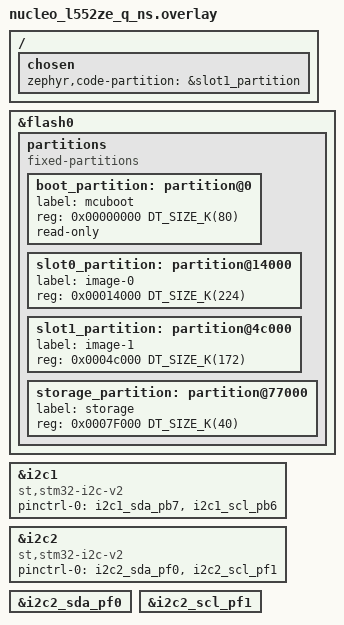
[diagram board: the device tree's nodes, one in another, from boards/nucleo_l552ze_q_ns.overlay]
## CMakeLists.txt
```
cmake_minimum_required(VERSION 3.20.0)

find_package(Zephyr REQUIRED HINTS $ENV{ZEPHYR_BASE})
project(i2c_sensor_trusted)

target_sources(app PRIVATE
  src/main.c
  src/trusted_peripheral_ns.c
)

# NOTE force test flash layout for more flash memory
set_property(TARGET zephyr_property_target
             APPEND PROPERTY TFM_CMAKE_OPTIONS
             -DTFM_S_REG_TEST=ON
)

get_target_property(TFM_BINARY_DIR tfm TFM_BINARY_DIR)
configure_file(
  ${CMAKE_CURRENT_LIST_DIR}/trusted_peripheral/tfm_manifest_list.yaml.in
  ${CMAKE_CURRENT_BINARY_DIR}/trusted_peripheral/tfm_manifest_list.yaml
)

set_property(TARGET zephyr_property_target
  APPEND PROPERTY TFM_CMAKE_OPTIONS
  -DTFM_EXTRA_MANIFEST_LIST_FILES=${CMAKE_CURRENT_BINARY_DIR}/trusted_peripheral/tfm_manifest_list.yaml
  -DTFM_EXTRA_PARTITION_PATHS=${CMAKE_CURRENT_LIST_DIR}/trusted_peripheral
)

# include folder that has tfm_api.h
target_include_directories(app PRIVATE
  $<TARGET_PROPERTY:tfm,TFM_BINARY_DIR>/install/interface/include
)

target_compile_definitions(app
    PRIVATE TFM_PARTITION_TRUSTED_PERIPHERAL
)
```

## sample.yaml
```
sample:
  name: Hello trusted I2C
```

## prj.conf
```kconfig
#
# SENSOR
#
CONFIG_GPIO=y
CONFIG_I2C=y
CONFIG_I2C_STM32=y

CONFIG_SPI=y
CONFIG_SPI_STM32=y

# NOTE a combination of these enables "%f" for printk
CONFIG_SHELL=y
CONFIG_I2C_SHELL=y
CONFIG_SENSOR_SHELL=y
CONFIG_SENSOR=y

#
# PARTITION
#
CONFIG_BUILD_WITH_TFM=y
CONFIG_TFM_PROFILE_TYPE_NOT_SET=y

# The TF-M build system produces an interface source file for accessing
# connection based services. Select this option when TF-M service models
# requires this source file. Note: This is an auto-generated configuration in
# the TF-M build system. When this option is not enabled in the TF-M build
# system this will result in compilation error.
CONFIG_TFM_CONNECTION_BASED_SERVICE_API=y
```

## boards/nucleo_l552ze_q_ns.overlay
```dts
/ {
	chosen {
		zephyr,code-partition = &slot1_partition;
	};
};

&flash0 {

	partitions {
		compatible = "fixed-partitions";
		#address-cells = <1>;
		#size-cells = <1>;

		boot_partition: partition@0 {
			label = "mcuboot";
			reg = <0x00000000 DT_SIZE_K(80)>;
			read-only;
		};
		/* Secure image primary slot */
		slot0_partition: partition@14000 {
			label = "image-0";
			reg = <0x00014000 DT_SIZE_K(224)>;
		};
		/* Non-secure image primary slot */
		slot1_partition: partition@4c000 {
			label = "image-1";
			reg = <0x0004c000 DT_SIZE_K(172)>;
		};
		/*
		 * The flash starting at 0x7F000 and ending at
		 * 0x80000 is reserved for the application.
		 */
		storage_partition: partition@77000 {
			label = "storage";
			reg = <0x0007F000 DT_SIZE_K(40)>;
		};
	};
};

&i2c1 {
			compatible = "st,stm32-i2c-v2";
            status = "okay";
            /* sda-pin = <26>; */
            /* scl-pin = <27>; */

            /* pinctrl-0 = <>; */
            pinctrl-0 = <&i2c1_sda_pb7 &i2c1_scl_pb6>;
            pinctrl-names = "default";
};

&i2c2 {
			compatible = "st,stm32-i2c-v2";
            status = "okay";
            /* sda-pin = <26>; */
            /* scl-pin = <27>; */

            pinctrl-0 = <&i2c2_sda_pf0 &i2c2_scl_pf1>;
            pinctrl-names = "default";
};

&i2c2_sda_pf0 {
            /* /delete-property/ bias-pull-up;     */
            /* /delete-property/ drive-open-drain; */
};

&i2c2_scl_pf1 {
            /* /delete-property/ bias-pull-up;     */
            /* /delete-property/ drive-open-drain; */
            /* bias-disable */
            /* bias-pull-up */
            /* bias-pull-down */
            /* drive-push-pull */
            /* drive-open-drain */
            /* output-low */
            /* output-high */
};
```

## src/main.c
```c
#include <zephyr/kernel.h>

/* partition includes */
#include <tfm_ns_interface.h>
#include "trusted_peripheral_ns.h"

/* sensor includes */
#include <zephyr/device.h>
#include <zephyr/drivers/gpio.h>
#include <zephyr/drivers/i2c.h>
#define I2C_SLAVE_ADDR 0x28


/* TODO duplicated on secure side */
#define MAC_HASH_SIZE 256
typedef struct {
    uint8_t buf[MAC_HASH_SIZE];  /* lets assume our data packet fits into this buffer */
} tp_mac_t;

int main(void)
{
    tp_mac_t mac = {0};

    /* sensor code */
    for (;;)
    {
        uint32_t tick_begin = HAL_GetTick(); /* TODO by default the tick increments for every ms.
                                              * is that accurate enough to measure performance ? */

        float sensor_temperature = 0.0f;
        float sensor_humidity    = 0.0f;

        /* i2c code in secure code */
        psa_status_t ret = tp_sensor_data_get(&sensor_temperature, &sensor_humidity, &mac, sizeof(tp_mac_t));
        if (ret != PSA_SUCCESS) {
            printk("Getting sensor data failed with status: %i\n", ret);
        }

        uint32_t tick_end = HAL_GetTick();
        printk("(%u ms) ", tick_end - tick_begin);

        printk("Temp: %f ", sensor_temperature);
        printk("Humidity: %f\n", sensor_humidity);

        /*
        printk("MAC: ");
        for (int i = 0; i < 32; i++)
        {
            printk("%02x", mac.buf[i]);
        }
        printk("\n");
        */
    }

    return 0;
}
```

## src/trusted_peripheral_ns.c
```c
#include <tfm_ns_interface.h>

#include "trusted_peripheral_ns.h"

#if defined(CONFIG_TFM_IPC)
#include "psa/client.h"
#include "psa_manifest/sid.h"
#endif

psa_status_t tp_sensor_data_get(float* temp, float* humidity, void* mac, size_t mac_size)
{
    psa_status_t status;
    psa_handle_t handle;

    psa_invec  in_vec[]  = { { .base = NULL, .len = 0 } }; // input parameter
    psa_outvec out_vec[] = {
        { .base = temp,     .len = sizeof(temp)   },
        { .base = humidity, .len = sizeof(humidity)   },
        { .base = mac,      .len = mac_size   }, // causes psa error
    }; // output parameter

#if defined(CONFIG_TFM_IPC)
    handle = psa_connect(TFM_TP_SENSOR_DATA_GET_SID, TFM_TP_SENSOR_DATA_GET_VERSION);
    if (!PSA_HANDLE_IS_VALID(handle)) { return PSA_ERROR_GENERIC_ERROR; }
    status = psa_call(handle, PSA_IPC_CALL, in_vec, IOVEC_LEN(in_vec), out_vec, IOVEC_LEN(out_vec));
    psa_close(handle);
#else
    /* NOTE SFN version would look like this */
    //status = tfm_ns_interface_dispatch((veneer_fn)..._veneer,
    //                                   (uint32_t)in_vec,  IOVEC_LEN(in_vec),
    //                                   (uint32_t)out_vec, IOVEC_LEN(out_vec));
#endif

    return status;
}
```

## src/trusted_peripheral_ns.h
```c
#include "tfm_api.h"

psa_status_t tp_sensor_data_get(float* temp, float* humidity,
                                void* mac, size_t mac_size);
```
